# ESP32-S31 register map
Vendor: ESPRESSIF SYSTEMS (SHANGHAI) CO., LTD.; Series: ESP32 S-Series; File version: 1
CPU: RV32IMAFC r0p0, little endian, no MPU, FPU, 0 interrupt priority bits
Address unit: 32 bits
Registers are 32-bit, read-write, reset 0x0 unless marked. A register's access mark holds for its fields unless they carry their own. Offsets are from the block's base; [hi:lo] are bit positions; {n}, {i} and the like mark numbered series.

## SOC_ETM (part 4 of 4) — Event Task Matrix
Base 0x20393000
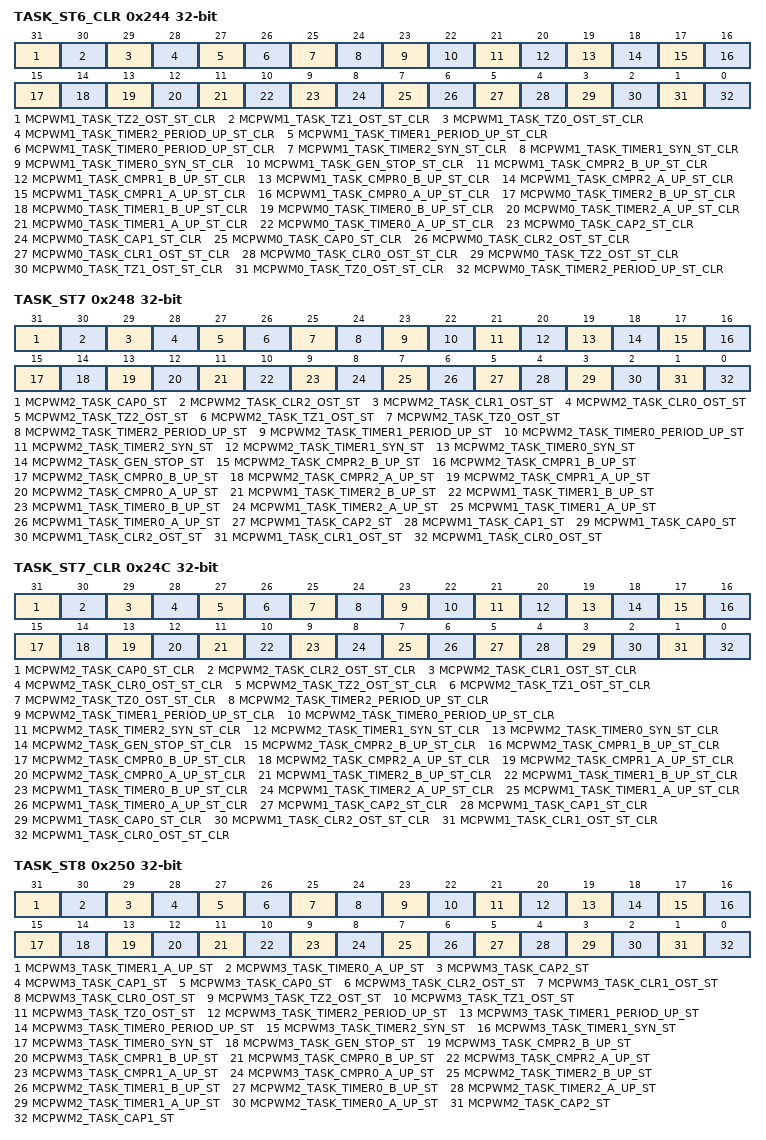
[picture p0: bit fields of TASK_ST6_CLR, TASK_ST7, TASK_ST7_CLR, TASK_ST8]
0x244 TASK_ST6_CLR wo — Tasks trigger status clear register
  [31] MCPWM1_TASK_TZ2_OST_ST_CLR — Configures whether or not to clear MCPWM1_task_tz2_ost trigger status.\\0: Invalid, No effect\\1: Clear
  [30] MCPWM1_TASK_TZ1_OST_ST_CLR — Configures whether or not to clear MCPWM1_task_tz1_ost trigger status.\\0: Invalid, No effect\\1: Clear
  [29] MCPWM1_TASK_TZ0_OST_ST_CLR — Configures whether or not to clear MCPWM1_task_tz0_ost trigger status.\\0: Invalid, No effect\\1: Clear
  [28] MCPWM1_TASK_TIMER2_PERIOD_UP_ST_CLR — Configures whether or not to clear MCPWM1_task_timer2_period_up trigger status.\\0: Invalid, No effect\\1: Clear
  [27] MCPWM1_TASK_TIMER1_PERIOD_UP_ST_CLR — Configures whether or not to clear MCPWM1_task_timer1_period_up trigger status.\\0: Invalid, No effect\\1: Clear
  [26] MCPWM1_TASK_TIMER0_PERIOD_UP_ST_CLR — Configures whether or not to clear MCPWM1_task_timer0_period_up trigger status.\\0: Invalid, No effect\\1: Clear
  [25] MCPWM1_TASK_TIMER2_SYN_ST_CLR — Configures whether or not to clear MCPWM1_task_timer2_syn trigger status.\\0: Invalid, No effect\\1: Clear
  [24] MCPWM1_TASK_TIMER1_SYN_ST_CLR — Configures whether or not to clear MCPWM1_task_timer1_syn trigger status.\\0: Invalid, No effect\\1: Clear
  [23] MCPWM1_TASK_TIMER0_SYN_ST_CLR — Configures whether or not to clear MCPWM1_task_timer0_syn trigger status.\\0: Invalid, No effect\\1: Clear
  [22] MCPWM1_TASK_GEN_STOP_ST_CLR — Configures whether or not to clear MCPWM1_task_gen_stop trigger status.\\0: Invalid, No effect\\1: Clear
  [21] MCPWM1_TASK_CMPR2_B_UP_ST_CLR — Configures whether or not to clear MCPWM1_task_cmpr2_b_up trigger status.\\0: Invalid, No effect\\1: Clear
  [20] MCPWM1_TASK_CMPR1_B_UP_ST_CLR — Configures whether or not to clear MCPWM1_task_cmpr1_b_up trigger status.\\0: Invalid, No effect\\1: Clear
  [19] MCPWM1_TASK_CMPR0_B_UP_ST_CLR — Configures whether or not to clear MCPWM1_task_cmpr0_b_up trigger status.\\0: Invalid, No effect\\1: Clear
  [18] MCPWM1_TASK_CMPR2_A_UP_ST_CLR — Configures whether or not to clear MCPWM1_task_cmpr2_a_up trigger status.\\0: Invalid, No effect\\1: Clear
  [17] MCPWM1_TASK_CMPR1_A_UP_ST_CLR — Configures whether or not to clear MCPWM1_task_cmpr1_a_up trigger status.\\0: Invalid, No effect\\1: Clear
  [16] MCPWM1_TASK_CMPR0_A_UP_ST_CLR — Configures whether or not to clear MCPWM1_task_cmpr0_a_up trigger status.\\0: Invalid, No effect\\1: Clear
  [15] MCPWM0_TASK_TIMER2_B_UP_ST_CLR — Configures whether or not to clear MCPWM0_task_timer2_b_up trigger status.\\0: Invalid, No effect\\1: Clear
  [14] MCPWM0_TASK_TIMER1_B_UP_ST_CLR — Configures whether or not to clear MCPWM0_task_timer1_b_up trigger status.\\0: Invalid, No effect\\1: Clear
  [13] MCPWM0_TASK_TIMER0_B_UP_ST_CLR — Configures whether or not to clear MCPWM0_task_timer0_b_up trigger status.\\0: Invalid, No effect\\1: Clear
  [12] MCPWM0_TASK_TIMER2_A_UP_ST_CLR — Configures whether or not to clear MCPWM0_task_timer2_a_up trigger status.\\0: Invalid, No effect\\1: Clear
  [11] MCPWM0_TASK_TIMER1_A_UP_ST_CLR — Configures whether or not to clear MCPWM0_task_timer1_a_up trigger status.\\0: Invalid, No effect\\1: Clear
  [10] MCPWM0_TASK_TIMER0_A_UP_ST_CLR — Configures whether or not to clear MCPWM0_task_timer0_a_up trigger status.\\0: Invalid, No effect\\1: Clear
  [9] MCPWM0_TASK_CAP2_ST_CLR — Configures whether or not to clear MCPWM0_task_cap2 trigger status.\\0: Invalid, No effect\\1: Clear
  [8] MCPWM0_TASK_CAP1_ST_CLR — Configures whether or not to clear MCPWM0_task_cap1 trigger status.\\0: Invalid, No effect\\1: Clear
  [7] MCPWM0_TASK_CAP0_ST_CLR — Configures whether or not to clear MCPWM0_task_cap0 trigger status.\\0: Invalid, No effect\\1: Clear
  [6] MCPWM0_TASK_CLR2_OST_ST_CLR — Configures whether or not to clear MCPWM0_task_clr2_ost trigger status.\\0: Invalid, No effect\\1: Clear
  [5] MCPWM0_TASK_CLR1_OST_ST_CLR — Configures whether or not to clear MCPWM0_task_clr1_ost trigger status.\\0: Invalid, No effect\\1: Clear
  [4] MCPWM0_TASK_CLR0_OST_ST_CLR — Configures whether or not to clear MCPWM0_task_clr0_ost trigger status.\\0: Invalid, No effect\\1: Clear
  [3] MCPWM0_TASK_TZ2_OST_ST_CLR — Configures whether or not to clear MCPWM0_task_tz2_ost trigger status.\\0: Invalid, No effect\\1: Clear
  [2] MCPWM0_TASK_TZ1_OST_ST_CLR — Configures whether or not to clear MCPWM0_task_tz1_ost trigger status.\\0: Invalid, No effect\\1: Clear
  [1] MCPWM0_TASK_TZ0_OST_ST_CLR — Configures whether or not to clear MCPWM0_task_tz0_ost trigger status.\\0: Invalid, No effect\\1: Clear
  [0] MCPWM0_TASK_TIMER2_PERIOD_UP_ST_CLR — Configures whether or not to clear MCPWM0_task_timer2_period_up trigger status.\\0: Invalid, No effect\\1: Clear
0x248 TASK_ST7 — Tasks trigger status register
  [31] MCPWM2_TASK_CAP0_ST — Represents MCPWM2_task_cap0 trigger status.\\0: Not triggered\\1: Triggered
  [30] MCPWM2_TASK_CLR2_OST_ST — Represents MCPWM2_task_clr2_ost trigger status.\\0: Not triggered\\1: Triggered
  [29] MCPWM2_TASK_CLR1_OST_ST — Represents MCPWM2_task_clr1_ost trigger status.\\0: Not triggered\\1: Triggered
  [28] MCPWM2_TASK_CLR0_OST_ST — Represents MCPWM2_task_clr0_ost trigger status.\\0: Not triggered\\1: Triggered
  [27] MCPWM2_TASK_TZ2_OST_ST — Represents MCPWM2_task_tz2_ost trigger status.\\0: Not triggered\\1: Triggered
  [26] MCPWM2_TASK_TZ1_OST_ST — Represents MCPWM2_task_tz1_ost trigger status.\\0: Not triggered\\1: Triggered
  [25] MCPWM2_TASK_TZ0_OST_ST — Represents MCPWM2_task_tz0_ost trigger status.\\0: Not triggered\\1: Triggered
  [24] MCPWM2_TASK_TIMER2_PERIOD_UP_ST — Represents MCPWM2_task_timer2_period_up trigger status.\\0: Not triggered\\1: Triggered
  [23] MCPWM2_TASK_TIMER1_PERIOD_UP_ST — Represents MCPWM2_task_timer1_period_up trigger status.\\0: Not triggered\\1: Triggered
  [22] MCPWM2_TASK_TIMER0_PERIOD_UP_ST — Represents MCPWM2_task_timer0_period_up trigger status.\\0: Not triggered\\1: Triggered
  [21] MCPWM2_TASK_TIMER2_SYN_ST — Represents MCPWM2_task_timer2_syn trigger status.\\0: Not triggered\\1: Triggered
  [20] MCPWM2_TASK_TIMER1_SYN_ST — Represents MCPWM2_task_timer1_syn trigger status.\\0: Not triggered\\1: Triggered
  [19] MCPWM2_TASK_TIMER0_SYN_ST — Represents MCPWM2_task_timer0_syn trigger status.\\0: Not triggered\\1: Triggered
  [18] MCPWM2_TASK_GEN_STOP_ST — Represents MCPWM2_task_gen_stop trigger status.\\0: Not triggered\\1: Triggered
  [17] MCPWM2_TASK_CMPR2_B_UP_ST — Represents MCPWM2_task_cmpr2_b_up trigger status.\\0: Not triggered\\1: Triggered
  [16] MCPWM2_TASK_CMPR1_B_UP_ST — Represents MCPWM2_task_cmpr1_b_up trigger status.\\0: Not triggered\\1: Triggered
  [15] MCPWM2_TASK_CMPR0_B_UP_ST — Represents MCPWM2_task_cmpr0_b_up trigger status.\\0: Not triggered\\1: Triggered
  [14] MCPWM2_TASK_CMPR2_A_UP_ST — Represents MCPWM2_task_cmpr2_a_up trigger status.\\0: Not triggered\\1: Triggered
  [13] MCPWM2_TASK_CMPR1_A_UP_ST — Represents MCPWM2_task_cmpr1_a_up trigger status.\\0: Not triggered\\1: Triggered
  [12] MCPWM2_TASK_CMPR0_A_UP_ST — Represents MCPWM2_task_cmpr0_a_up trigger status.\\0: Not triggered\\1: Triggered
  [11] MCPWM1_TASK_TIMER2_B_UP_ST — Represents MCPWM1_task_timer2_b_up trigger status.\\0: Not triggered\\1: Triggered
  [10] MCPWM1_TASK_TIMER1_B_UP_ST — Represents MCPWM1_task_timer1_b_up trigger status.\\0: Not triggered\\1: Triggered
  [9] MCPWM1_TASK_TIMER0_B_UP_ST — Represents MCPWM1_task_timer0_b_up trigger status.\\0: Not triggered\\1: Triggered
  [8] MCPWM1_TASK_TIMER2_A_UP_ST — Represents MCPWM1_task_timer2_a_up trigger status.\\0: Not triggered\\1: Triggered
  [7] MCPWM1_TASK_TIMER1_A_UP_ST — Represents MCPWM1_task_timer1_a_up trigger status.\\0: Not triggered\\1: Triggered
  [6] MCPWM1_TASK_TIMER0_A_UP_ST — Represents MCPWM1_task_timer0_a_up trigger status.\\0: Not triggered\\1: Triggered
  [5] MCPWM1_TASK_CAP2_ST — Represents MCPWM1_task_cap2 trigger status.\\0: Not triggered\\1: Triggered
  [4] MCPWM1_TASK_CAP1_ST — Represents MCPWM1_task_cap1 trigger status.\\0: Not triggered\\1: Triggered
  [3] MCPWM1_TASK_CAP0_ST — Represents MCPWM1_task_cap0 trigger status.\\0: Not triggered\\1: Triggered
  [2] MCPWM1_TASK_CLR2_OST_ST — Represents MCPWM1_task_clr2_ost trigger status.\\0: Not triggered\\1: Triggered
  [1] MCPWM1_TASK_CLR1_OST_ST — Represents MCPWM1_task_clr1_ost trigger status.\\0: Not triggered\\1: Triggered
  [0] MCPWM1_TASK_CLR0_OST_ST — Represents MCPWM1_task_clr0_ost trigger status.\\0: Not triggered\\1: Triggered
0x24C TASK_ST7_CLR wo — Tasks trigger status clear register
  [31] MCPWM2_TASK_CAP0_ST_CLR — Configures whether or not to clear MCPWM2_task_cap0 trigger status.\\0: Invalid, No effect\\1: Clear
  [30] MCPWM2_TASK_CLR2_OST_ST_CLR — Configures whether or not to clear MCPWM2_task_clr2_ost trigger status.\\0: Invalid, No effect\\1: Clear
  [29] MCPWM2_TASK_CLR1_OST_ST_CLR — Configures whether or not to clear MCPWM2_task_clr1_ost trigger status.\\0: Invalid, No effect\\1: Clear
  [28] MCPWM2_TASK_CLR0_OST_ST_CLR — Configures whether or not to clear MCPWM2_task_clr0_ost trigger status.\\0: Invalid, No effect\\1: Clear
  [27] MCPWM2_TASK_TZ2_OST_ST_CLR — Configures whether or not to clear MCPWM2_task_tz2_ost trigger status.\\0: Invalid, No effect\\1: Clear
  [26] MCPWM2_TASK_TZ1_OST_ST_CLR — Configures whether or not to clear MCPWM2_task_tz1_ost trigger status.\\0: Invalid, No effect\\1: Clear
  [25] MCPWM2_TASK_TZ0_OST_ST_CLR — Configures whether or not to clear MCPWM2_task_tz0_ost trigger status.\\0: Invalid, No effect\\1: Clear
  [24] MCPWM2_TASK_TIMER2_PERIOD_UP_ST_CLR — Configures whether or not to clear MCPWM2_task_timer2_period_up trigger status.\\0: Invalid, No effect\\1: Clear
  [23] MCPWM2_TASK_TIMER1_PERIOD_UP_ST_CLR — Configures whether or not to clear MCPWM2_task_timer1_period_up trigger status.\\0: Invalid, No effect\\1: Clear
  [22] MCPWM2_TASK_TIMER0_PERIOD_UP_ST_CLR — Configures whether or not to clear MCPWM2_task_timer0_period_up trigger status.\\0: Invalid, No effect\\1: Clear
  [21] MCPWM2_TASK_TIMER2_SYN_ST_CLR — Configures whether or not to clear MCPWM2_task_timer2_syn trigger status.\\0: Invalid, No effect\\1: Clear
  [20] MCPWM2_TASK_TIMER1_SYN_ST_CLR — Configures whether or not to clear MCPWM2_task_timer1_syn trigger status.\\0: Invalid, No effect\\1: Clear
  [19] MCPWM2_TASK_TIMER0_SYN_ST_CLR — Configures whether or not to clear MCPWM2_task_timer0_syn trigger status.\\0: Invalid, No effect\\1: Clear
  [18] MCPWM2_TASK_GEN_STOP_ST_CLR — Configures whether or not to clear MCPWM2_task_gen_stop trigger status.\\0: Invalid, No effect\\1: Clear
  [17] MCPWM2_TASK_CMPR2_B_UP_ST_CLR — Configures whether or not to clear MCPWM2_task_cmpr2_b_up trigger status.\\0: Invalid, No effect\\1: Clear
  [16] MCPWM2_TASK_CMPR1_B_UP_ST_CLR — Configures whether or not to clear MCPWM2_task_cmpr1_b_up trigger status.\\0: Invalid, No effect\\1: Clear
  [15] MCPWM2_TASK_CMPR0_B_UP_ST_CLR — Configures whether or not to clear MCPWM2_task_cmpr0_b_up trigger status.\\0: Invalid, No effect\\1: Clear
  [14] MCPWM2_TASK_CMPR2_A_UP_ST_CLR — Configures whether or not to clear MCPWM2_task_cmpr2_a_up trigger status.\\0: Invalid, No effect\\1: Clear
  [13] MCPWM2_TASK_CMPR1_A_UP_ST_CLR — Configures whether or not to clear MCPWM2_task_cmpr1_a_up trigger status.\\0: Invalid, No effect\\1: Clear
  [12] MCPWM2_TASK_CMPR0_A_UP_ST_CLR — Configures whether or not to clear MCPWM2_task_cmpr0_a_up trigger status.\\0: Invalid, No effect\\1: Clear
  [11] MCPWM1_TASK_TIMER2_B_UP_ST_CLR — Configures whether or not to clear MCPWM1_task_timer2_b_up trigger status.\\0: Invalid, No effect\\1: Clear
  [10] MCPWM1_TASK_TIMER1_B_UP_ST_CLR — Configures whether or not to clear MCPWM1_task_timer1_b_up trigger status.\\0: Invalid, No effect\\1: Clear
  [9] MCPWM1_TASK_TIMER0_B_UP_ST_CLR — Configures whether or not to clear MCPWM1_task_timer0_b_up trigger status.\\0: Invalid, No effect\\1: Clear
  [8] MCPWM1_TASK_TIMER2_A_UP_ST_CLR — Configures whether or not to clear MCPWM1_task_timer2_a_up trigger status.\\0: Invalid, No effect\\1: Clear
  [7] MCPWM1_TASK_TIMER1_A_UP_ST_CLR — Configures whether or not to clear MCPWM1_task_timer1_a_up trigger status.\\0: Invalid, No effect\\1: Clear
  [6] MCPWM1_TASK_TIMER0_A_UP_ST_CLR — Configures whether or not to clear MCPWM1_task_timer0_a_up trigger status.\\0: Invalid, No effect\\1: Clear
  [5] MCPWM1_TASK_CAP2_ST_CLR — Configures whether or not to clear MCPWM1_task_cap2 trigger status.\\0: Invalid, No effect\\1: Clear
  [4] MCPWM1_TASK_CAP1_ST_CLR — Configures whether or not to clear MCPWM1_task_cap1 trigger status.\\0: Invalid, No effect\\1: Clear
  [3] MCPWM1_TASK_CAP0_ST_CLR — Configures whether or not to clear MCPWM1_task_cap0 trigger status.\\0: Invalid, No effect\\1: Clear
  [2] MCPWM1_TASK_CLR2_OST_ST_CLR — Configures whether or not to clear MCPWM1_task_clr2_ost trigger status.\\0: Invalid, No effect\\1: Clear
  [1] MCPWM1_TASK_CLR1_OST_ST_CLR — Configures whether or not to clear MCPWM1_task_clr1_ost trigger status.\\0: Invalid, No effect\\1: Clear
  [0] MCPWM1_TASK_CLR0_OST_ST_CLR — Configures whether or not to clear MCPWM1_task_clr0_ost trigger status.\\0: Invalid, No effect\\1: Clear
0x250 TASK_ST8 — Tasks trigger status register
  [31] MCPWM3_TASK_TIMER1_A_UP_ST — Represents MCPWM3_task_timer1_a_up trigger status.\\0: Not triggered\\1: Triggered
  [30] MCPWM3_TASK_TIMER0_A_UP_ST — Represents MCPWM3_task_timer0_a_up trigger status.\\0: Not triggered\\1: Triggered
  [29] MCPWM3_TASK_CAP2_ST — Represents MCPWM3_task_cap2 trigger status.\\0: Not triggered\\1: Triggered
  [28] MCPWM3_TASK_CAP1_ST — Represents MCPWM3_task_cap1 trigger status.\\0: Not triggered\\1: Triggered
  [27] MCPWM3_TASK_CAP0_ST — Represents MCPWM3_task_cap0 trigger status.\\0: Not triggered\\1: Triggered
  [26] MCPWM3_TASK_CLR2_OST_ST — Represents MCPWM3_task_clr2_ost trigger status.\\0: Not triggered\\1: Triggered
  [25] MCPWM3_TASK_CLR1_OST_ST — Represents MCPWM3_task_clr1_ost trigger status.\\0: Not triggered\\1: Triggered
  [24] MCPWM3_TASK_CLR0_OST_ST — Represents MCPWM3_task_clr0_ost trigger status.\\0: Not triggered\\1: Triggered
  [23] MCPWM3_TASK_TZ2_OST_ST — Represents MCPWM3_task_tz2_ost trigger status.\\0: Not triggered\\1: Triggered
  [22] MCPWM3_TASK_TZ1_OST_ST — Represents MCPWM3_task_tz1_ost trigger status.\\0: Not triggered\\1: Triggered
  [21] MCPWM3_TASK_TZ0_OST_ST — Represents MCPWM3_task_tz0_ost trigger status.\\0: Not triggered\\1: Triggered
  [20] MCPWM3_TASK_TIMER2_PERIOD_UP_ST — Represents MCPWM3_task_timer2_period_up trigger status.\\0: Not triggered\\1: Triggered
  [19] MCPWM3_TASK_TIMER1_PERIOD_UP_ST — Represents MCPWM3_task_timer1_period_up trigger status.\\0: Not triggered\\1: Triggered
  [18] MCPWM3_TASK_TIMER0_PERIOD_UP_ST — Represents MCPWM3_task_timer0_period_up trigger status.\\0: Not triggered\\1: Triggered
  [17] MCPWM3_TASK_TIMER2_SYN_ST — Represents MCPWM3_task_timer2_syn trigger status.\\0: Not triggered\\1: Triggered
  [16] MCPWM3_TASK_TIMER1_SYN_ST — Represents MCPWM3_task_timer1_syn trigger status.\\0: Not triggered\\1: Triggered
  [15] MCPWM3_TASK_TIMER0_SYN_ST — Represents MCPWM3_task_timer0_syn trigger status.\\0: Not triggered\\1: Triggered
  [14] MCPWM3_TASK_GEN_STOP_ST — Represents MCPWM3_task_gen_stop trigger status.\\0: Not triggered\\1: Triggered
  [13] MCPWM3_TASK_CMPR2_B_UP_ST — Represents MCPWM3_task_cmpr2_b_up trigger status.\\0: Not triggered\\1: Triggered
  [12] MCPWM3_TASK_CMPR1_B_UP_ST — Represents MCPWM3_task_cmpr1_b_up trigger status.\\0: Not triggered\\1: Triggered
  [11] MCPWM3_TASK_CMPR0_B_UP_ST — Represents MCPWM3_task_cmpr0_b_up trigger status.\\0: Not triggered\\1: Triggered
  [10] MCPWM3_TASK_CMPR2_A_UP_ST — Represents MCPWM3_task_cmpr2_a_up trigger status.\\0: Not triggered\\1: Triggered
  [9] MCPWM3_TASK_CMPR1_A_UP_ST — Represents MCPWM3_task_cmpr1_a_up trigger status.\\0: Not triggered\\1: Triggered
  [8] MCPWM3_TASK_CMPR0_A_UP_ST — Represents MCPWM3_task_cmpr0_a_up trigger status.\\0: Not triggered\\1: Triggered
  [7] MCPWM2_TASK_TIMER2_B_UP_ST — Represents MCPWM2_task_timer2_b_up trigger status.\\0: Not triggered\\1: Triggered
  [6] MCPWM2_TASK_TIMER1_B_UP_ST — Represents MCPWM2_task_timer1_b_up trigger status.\\0: Not triggered\\1: Triggered
  [5] MCPWM2_TASK_TIMER0_B_UP_ST — Represents MCPWM2_task_timer0_b_up trigger status.\\0: Not triggered\\1: Triggered
  [4] MCPWM2_TASK_TIMER2_A_UP_ST — Represents MCPWM2_task_timer2_a_up trigger status.\\0: Not triggered\\1: Triggered
  [3] MCPWM2_TASK_TIMER1_A_UP_ST — Represents MCPWM2_task_timer1_a_up trigger status.\\0: Not triggered\\1: Triggered
  [2] MCPWM2_TASK_TIMER0_A_UP_ST — Represents MCPWM2_task_timer0_a_up trigger status.\\0: Not triggered\\1: Triggered
  [1] MCPWM2_TASK_CAP2_ST — Represents MCPWM2_task_cap2 trigger status.\\0: Not triggered\\1: Triggered
  [0] MCPWM2_TASK_CAP1_ST — Represents MCPWM2_task_cap1 trigger status.\\0: Not triggered\\1: Triggered
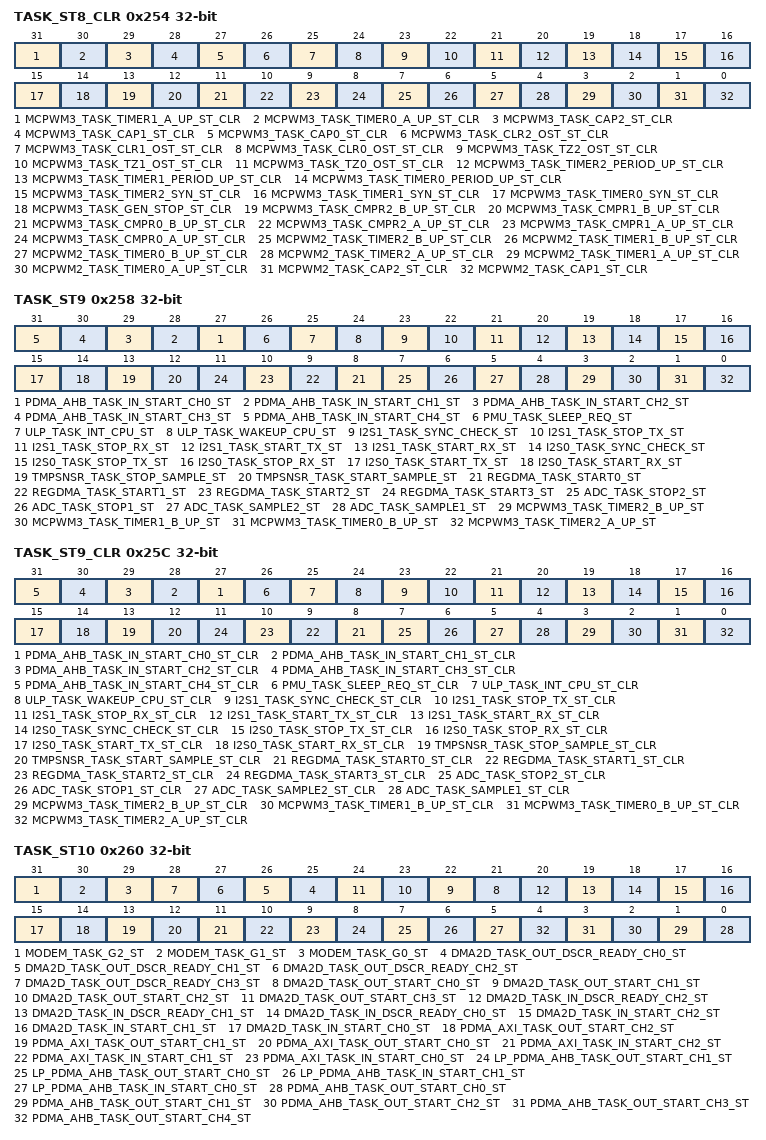
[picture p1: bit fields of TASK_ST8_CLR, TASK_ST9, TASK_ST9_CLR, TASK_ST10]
0x254 TASK_ST8_CLR wo — Tasks trigger status clear register
  [31] MCPWM3_TASK_TIMER1_A_UP_ST_CLR — Configures whether or not to clear MCPWM3_task_timer1_a_up trigger status.\\0: Invalid, No effect\\1: Clear
  [30] MCPWM3_TASK_TIMER0_A_UP_ST_CLR — Configures whether or not to clear MCPWM3_task_timer0_a_up trigger status.\\0: Invalid, No effect\\1: Clear
  [29] MCPWM3_TASK_CAP2_ST_CLR — Configures whether or not to clear MCPWM3_task_cap2 trigger status.\\0: Invalid, No effect\\1: Clear
  [28] MCPWM3_TASK_CAP1_ST_CLR — Configures whether or not to clear MCPWM3_task_cap1 trigger status.\\0: Invalid, No effect\\1: Clear
  [27] MCPWM3_TASK_CAP0_ST_CLR — Configures whether or not to clear MCPWM3_task_cap0 trigger status.\\0: Invalid, No effect\\1: Clear
  [26] MCPWM3_TASK_CLR2_OST_ST_CLR — Configures whether or not to clear MCPWM3_task_clr2_ost trigger status.\\0: Invalid, No effect\\1: Clear
  [25] MCPWM3_TASK_CLR1_OST_ST_CLR — Configures whether or not to clear MCPWM3_task_clr1_ost trigger status.\\0: Invalid, No effect\\1: Clear
  [24] MCPWM3_TASK_CLR0_OST_ST_CLR — Configures whether or not to clear MCPWM3_task_clr0_ost trigger status.\\0: Invalid, No effect\\1: Clear
  [23] MCPWM3_TASK_TZ2_OST_ST_CLR — Configures whether or not to clear MCPWM3_task_tz2_ost trigger status.\\0: Invalid, No effect\\1: Clear
  [22] MCPWM3_TASK_TZ1_OST_ST_CLR — Configures whether or not to clear MCPWM3_task_tz1_ost trigger status.\\0: Invalid, No effect\\1: Clear
  [21] MCPWM3_TASK_TZ0_OST_ST_CLR — Configures whether or not to clear MCPWM3_task_tz0_ost trigger status.\\0: Invalid, No effect\\1: Clear
  [20] MCPWM3_TASK_TIMER2_PERIOD_UP_ST_CLR — Configures whether or not to clear MCPWM3_task_timer2_period_up trigger status.\\0: Invalid, No effect\\1: Clear
  [19] MCPWM3_TASK_TIMER1_PERIOD_UP_ST_CLR — Configures whether or not to clear MCPWM3_task_timer1_period_up trigger status.\\0: Invalid, No effect\\1: Clear
  [18] MCPWM3_TASK_TIMER0_PERIOD_UP_ST_CLR — Configures whether or not to clear MCPWM3_task_timer0_period_up trigger status.\\0: Invalid, No effect\\1: Clear
  [17] MCPWM3_TASK_TIMER2_SYN_ST_CLR — Configures whether or not to clear MCPWM3_task_timer2_syn trigger status.\\0: Invalid, No effect\\1: Clear
  [16] MCPWM3_TASK_TIMER1_SYN_ST_CLR — Configures whether or not to clear MCPWM3_task_timer1_syn trigger status.\\0: Invalid, No effect\\1: Clear
  [15] MCPWM3_TASK_TIMER0_SYN_ST_CLR — Configures whether or not to clear MCPWM3_task_timer0_syn trigger status.\\0: Invalid, No effect\\1: Clear
  [14] MCPWM3_TASK_GEN_STOP_ST_CLR — Configures whether or not to clear MCPWM3_task_gen_stop trigger status.\\0: Invalid, No effect\\1: Clear
  [13] MCPWM3_TASK_CMPR2_B_UP_ST_CLR — Configures whether or not to clear MCPWM3_task_cmpr2_b_up trigger status.\\0: Invalid, No effect\\1: Clear
  [12] MCPWM3_TASK_CMPR1_B_UP_ST_CLR — Configures whether or not to clear MCPWM3_task_cmpr1_b_up trigger status.\\0: Invalid, No effect\\1: Clear
  [11] MCPWM3_TASK_CMPR0_B_UP_ST_CLR — Configures whether or not to clear MCPWM3_task_cmpr0_b_up trigger status.\\0: Invalid, No effect\\1: Clear
  [10] MCPWM3_TASK_CMPR2_A_UP_ST_CLR — Configures whether or not to clear MCPWM3_task_cmpr2_a_up trigger status.\\0: Invalid, No effect\\1: Clear
  [9] MCPWM3_TASK_CMPR1_A_UP_ST_CLR — Configures whether or not to clear MCPWM3_task_cmpr1_a_up trigger status.\\0: Invalid, No effect\\1: Clear
  [8] MCPWM3_TASK_CMPR0_A_UP_ST_CLR — Configures whether or not to clear MCPWM3_task_cmpr0_a_up trigger status.\\0: Invalid, No effect\\1: Clear
  [7] MCPWM2_TASK_TIMER2_B_UP_ST_CLR — Configures whether or not to clear MCPWM2_task_timer2_b_up trigger status.\\0: Invalid, No effect\\1: Clear
  [6] MCPWM2_TASK_TIMER1_B_UP_ST_CLR — Configures whether or not to clear MCPWM2_task_timer1_b_up trigger status.\\0: Invalid, No effect\\1: Clear
  [5] MCPWM2_TASK_TIMER0_B_UP_ST_CLR — Configures whether or not to clear MCPWM2_task_timer0_b_up trigger status.\\0: Invalid, No effect\\1: Clear
  [4] MCPWM2_TASK_TIMER2_A_UP_ST_CLR — Configures whether or not to clear MCPWM2_task_timer2_a_up trigger status.\\0: Invalid, No effect\\1: Clear
  [3] MCPWM2_TASK_TIMER1_A_UP_ST_CLR — Configures whether or not to clear MCPWM2_task_timer1_a_up trigger status.\\0: Invalid, No effect\\1: Clear
  [2] MCPWM2_TASK_TIMER0_A_UP_ST_CLR — Configures whether or not to clear MCPWM2_task_timer0_a_up trigger status.\\0: Invalid, No effect\\1: Clear
  [1] MCPWM2_TASK_CAP2_ST_CLR — Configures whether or not to clear MCPWM2_task_cap2 trigger status.\\0: Invalid, No effect\\1: Clear
  [0] MCPWM2_TASK_CAP1_ST_CLR — Configures whether or not to clear MCPWM2_task_cap1 trigger status.\\0: Invalid, No effect\\1: Clear
0x258 TASK_ST9 — Tasks trigger status register
  [n+27] PDMA_AHB_TASK_IN_START_CH{n}_ST (n=0..4) — Represents PDMA_AHB_task_in_start_ch{n} trigger status.\\0: Not triggered\\1: Triggered
  [26] PMU_TASK_SLEEP_REQ_ST — Represents PMU_task_sleep_req trigger status.\\0: Not triggered\\1: Triggered
  [25] ULP_TASK_INT_CPU_ST — Represents ULP_task_int_cpu trigger status.\\0: Not triggered\\1: Triggered
  [24] ULP_TASK_WAKEUP_CPU_ST — Represents ULP_task_wakeup_cpu trigger status.\\0: Not triggered\\1: Triggered
  [23] I2S1_TASK_SYNC_CHECK_ST — Represents I2S1_task_sync_check trigger status.\\0: Not triggered\\1: Triggered
  [22] I2S1_TASK_STOP_TX_ST — Represents I2S1_task_stop_tx trigger status.\\0: Not triggered\\1: Triggered
  [21] I2S1_TASK_STOP_RX_ST — Represents I2S1_task_stop_rx trigger status.\\0: Not triggered\\1: Triggered
  [20] I2S1_TASK_START_TX_ST — Represents I2S1_task_start_tx trigger status.\\0: Not triggered\\1: Triggered
  [19] I2S1_TASK_START_RX_ST — Represents I2S1_task_start_rx trigger status.\\0: Not triggered\\1: Triggered
  [18] I2S0_TASK_SYNC_CHECK_ST — Represents I2S0_task_sync_check trigger status.\\0: Not triggered\\1: Triggered
  [17] I2S0_TASK_STOP_TX_ST — Represents I2S0_task_stop_tx trigger status.\\0: Not triggered\\1: Triggered
  [16] I2S0_TASK_STOP_RX_ST — Represents I2S0_task_stop_rx trigger status.\\0: Not triggered\\1: Triggered
  [15] I2S0_TASK_START_TX_ST — Represents I2S0_task_start_tx trigger status.\\0: Not triggered\\1: Triggered
  [14] I2S0_TASK_START_RX_ST — Represents I2S0_task_start_rx trigger status.\\0: Not triggered\\1: Triggered
  [13] TMPSNSR_TASK_STOP_SAMPLE_ST — Represents TMPSNSR_task_stop_sample trigger status.\\0: Not triggered\\1: Triggered
  [12] TMPSNSR_TASK_START_SAMPLE_ST — Represents TMPSNSR_task_start_sample trigger status.\\0: Not triggered\\1: Triggered
  [n+8] REGDMA_TASK_START{n}_ST (n=0..3) — Represents REGDMA_task_start{n} trigger status.\\0: Not triggered\\1: Triggered
  [7] ADC_TASK_STOP2_ST — Represents ADC_task_stop2 trigger status.\\0: Not triggered\\1: Triggered
  [6] ADC_TASK_STOP1_ST — Represents ADC_task_stop1 trigger status.\\0: Not triggered\\1: Triggered
  [5] ADC_TASK_SAMPLE2_ST — Represents ADC_task_sample2 trigger status.\\0: Not triggered\\1: Triggered
  [4] ADC_TASK_SAMPLE1_ST — Represents ADC_task_sample1 trigger status.\\0: Not triggered\\1: Triggered
  [3] MCPWM3_TASK_TIMER2_B_UP_ST — Represents MCPWM3_task_timer2_b_up trigger status.\\0: Not triggered\\1: Triggered
  [2] MCPWM3_TASK_TIMER1_B_UP_ST — Represents MCPWM3_task_timer1_b_up trigger status.\\0: Not triggered\\1: Triggered
  [1] MCPWM3_TASK_TIMER0_B_UP_ST — Represents MCPWM3_task_timer0_b_up trigger status.\\0: Not triggered\\1: Triggered
  [0] MCPWM3_TASK_TIMER2_A_UP_ST — Represents MCPWM3_task_timer2_a_up trigger status.\\0: Not triggered\\1: Triggered
0x25C TASK_ST9_CLR wo — Tasks trigger status clear register
  [n+27] PDMA_AHB_TASK_IN_START_CH{n}_ST_CLR (n=0..4) — Configures whether or not to clear PDMA_AHB_task_in_start_ch{n} trigger status.\\0: Invalid, No effect\\1: Clear
  [26] PMU_TASK_SLEEP_REQ_ST_CLR — Configures whether or not to clear PMU_task_sleep_req trigger status.\\0: Invalid, No effect\\1: Clear
  [25] ULP_TASK_INT_CPU_ST_CLR — Configures whether or not to clear ULP_task_int_cpu trigger status.\\0: Invalid, No effect\\1: Clear
  [24] ULP_TASK_WAKEUP_CPU_ST_CLR — Configures whether or not to clear ULP_task_wakeup_cpu trigger status.\\0: Invalid, No effect\\1: Clear
  [23] I2S1_TASK_SYNC_CHECK_ST_CLR — Configures whether or not to clear I2S1_task_sync_check trigger status.\\0: Invalid, No effect\\1: Clear
  [22] I2S1_TASK_STOP_TX_ST_CLR — Configures whether or not to clear I2S1_task_stop_tx trigger status.\\0: Invalid, No effect\\1: Clear
  [21] I2S1_TASK_STOP_RX_ST_CLR — Configures whether or not to clear I2S1_task_stop_rx trigger status.\\0: Invalid, No effect\\1: Clear
  [20] I2S1_TASK_START_TX_ST_CLR — Configures whether or not to clear I2S1_task_start_tx trigger status.\\0: Invalid, No effect\\1: Clear
  [19] I2S1_TASK_START_RX_ST_CLR — Configures whether or not to clear I2S1_task_start_rx trigger status.\\0: Invalid, No effect\\1: Clear
  [18] I2S0_TASK_SYNC_CHECK_ST_CLR — Configures whether or not to clear I2S0_task_sync_check trigger status.\\0: Invalid, No effect\\1: Clear
  [17] I2S0_TASK_STOP_TX_ST_CLR — Configures whether or not to clear I2S0_task_stop_tx trigger status.\\0: Invalid, No effect\\1: Clear
  [16] I2S0_TASK_STOP_RX_ST_CLR — Configures whether or not to clear I2S0_task_stop_rx trigger status.\\0: Invalid, No effect\\1: Clear
  [15] I2S0_TASK_START_TX_ST_CLR — Configures whether or not to clear I2S0_task_start_tx trigger status.\\0: Invalid, No effect\\1: Clear
  [14] I2S0_TASK_START_RX_ST_CLR — Configures whether or not to clear I2S0_task_start_rx trigger status.\\0: Invalid, No effect\\1: Clear
  [13] TMPSNSR_TASK_STOP_SAMPLE_ST_CLR — Configures whether or not to clear TMPSNSR_task_stop_sample trigger status.\\0: Invalid, No effect\\1: Clear
  [12] TMPSNSR_TASK_START_SAMPLE_ST_CLR — Configures whether or not to clear TMPSNSR_task_start_sample trigger status.\\0: Invalid, No effect\\1: Clear
  [n+8] REGDMA_TASK_START{n}_ST_CLR (n=0..3) — Configures whether or not to clear REGDMA_task_start{n} trigger status.\\0: Invalid, No effect\\1: Clear
  [7] ADC_TASK_STOP2_ST_CLR — Configures whether or not to clear ADC_task_stop2 trigger status.\\0: Invalid, No effect\\1: Clear
  [6] ADC_TASK_STOP1_ST_CLR — Configures whether or not to clear ADC_task_stop1 trigger status.\\0: Invalid, No effect\\1: Clear
  [5] ADC_TASK_SAMPLE2_ST_CLR — Configures whether or not to clear ADC_task_sample2 trigger status.\\0: Invalid, No effect\\1: Clear
  [4] ADC_TASK_SAMPLE1_ST_CLR — Configures whether or not to clear ADC_task_sample1 trigger status.\\0: Invalid, No effect\\1: Clear
  [3] MCPWM3_TASK_TIMER2_B_UP_ST_CLR — Configures whether or not to clear MCPWM3_task_timer2_b_up trigger status.\\0: Invalid, No effect\\1: Clear
  [2] MCPWM3_TASK_TIMER1_B_UP_ST_CLR — Configures whether or not to clear MCPWM3_task_timer1_b_up trigger status.\\0: Invalid, No effect\\1: Clear
  [1] MCPWM3_TASK_TIMER0_B_UP_ST_CLR — Configures whether or not to clear MCPWM3_task_timer0_b_up trigger status.\\0: Invalid, No effect\\1: Clear
  [0] MCPWM3_TASK_TIMER2_A_UP_ST_CLR — Configures whether or not to clear MCPWM3_task_timer2_a_up trigger status.\\0: Invalid, No effect\\1: Clear
0x260 TASK_ST10 — Tasks trigger status register
  [31] MODEM_TASK_G2_ST — Represents MODEM_task_g2 trigger status.\\0: Not triggered\\1: Triggered
  [30] MODEM_TASK_G1_ST — Represents MODEM_task_g1 trigger status.\\0: Not triggered\\1: Triggered
  [29] MODEM_TASK_G0_ST — Represents MODEM_task_g0 trigger status.\\0: Not triggered\\1: Triggered
  [n+25] DMA2D_TASK_OUT_DSCR_READY_CH{n}_ST (n=0..3) — Represents DMA2D_task_out_dscr_ready_ch{n} trigger status.\\0: Not triggered\\1: Triggered
  [n+21] DMA2D_TASK_OUT_START_CH{n}_ST (n=0..3) — Represents DMA2D_task_out_start_ch{n} trigger status.\\0: Not triggered\\1: Triggered
  [20] DMA2D_TASK_IN_DSCR_READY_CH2_ST — Represents DMA2D_task_in_dscr_ready_ch2 trigger status.\\0: Not triggered\\1: Triggered
  [19] DMA2D_TASK_IN_DSCR_READY_CH1_ST — Represents DMA2D_task_in_dscr_ready_ch1 trigger status.\\0: Not triggered\\1: Triggered
  [18] DMA2D_TASK_IN_DSCR_READY_CH0_ST — Represents DMA2D_task_in_dscr_ready_ch0 trigger status.\\0: Not triggered\\1: Triggered
  [17] DMA2D_TASK_IN_START_CH2_ST — Represents DMA2D_task_in_start_ch2 trigger status.\\0: Not triggered\\1: Triggered
  [16] DMA2D_TASK_IN_START_CH1_ST — Represents DMA2D_task_in_start_ch1 trigger status.\\0: Not triggered\\1: Triggered
  [15] DMA2D_TASK_IN_START_CH0_ST — Represents DMA2D_task_in_start_ch0 trigger status.\\0: Not triggered\\1: Triggered
  [14] PDMA_AXI_TASK_OUT_START_CH2_ST — Represents PDMA_AXI_task_out_start_ch2 trigger status.\\0: Not triggered\\1: Triggered
  [13] PDMA_AXI_TASK_OUT_START_CH1_ST — Represents PDMA_AXI_task_out_start_ch1 trigger status.\\0: Not triggered\\1: Triggered
  [12] PDMA_AXI_TASK_OUT_START_CH0_ST — Represents PDMA_AXI_task_out_start_ch0 trigger status.\\0: Not triggered\\1: Triggered
  [11] PDMA_AXI_TASK_IN_START_CH2_ST — Represents PDMA_AXI_task_in_start_ch2 trigger status.\\0: Not triggered\\1: Triggered
  [10] PDMA_AXI_TASK_IN_START_CH1_ST — Represents PDMA_AXI_task_in_start_ch1 trigger status.\\0: Not triggered\\1: Triggered
  [9] PDMA_AXI_TASK_IN_START_CH0_ST — Represents PDMA_AXI_task_in_start_ch0 trigger status.\\0: Not triggered\\1: Triggered
  [8] LP_PDMA_AHB_TASK_OUT_START_CH1_ST — Represents LP_PDMA_AHB_task_out_start_ch1 trigger status.\\0: Not triggered\\1: Triggered
  [7] LP_PDMA_AHB_TASK_OUT_START_CH0_ST — Represents LP_PDMA_AHB_task_out_start_ch0 trigger status.\\0: Not triggered\\1: Triggered
  [6] LP_PDMA_AHB_TASK_IN_START_CH1_ST — Represents LP_PDMA_AHB_task_in_start_ch1 trigger status.\\0: Not triggered\\1: Triggered
  [5] LP_PDMA_AHB_TASK_IN_START_CH0_ST — Represents LP_PDMA_AHB_task_in_start_ch0 trigger status.\\0: Not triggered\\1: Triggered
  [n] PDMA_AHB_TASK_OUT_START_CH{n}_ST (n=0..4) — Represents PDMA_AHB_task_out_start_ch{n} trigger status.\\0: Not triggered\\1: Triggered
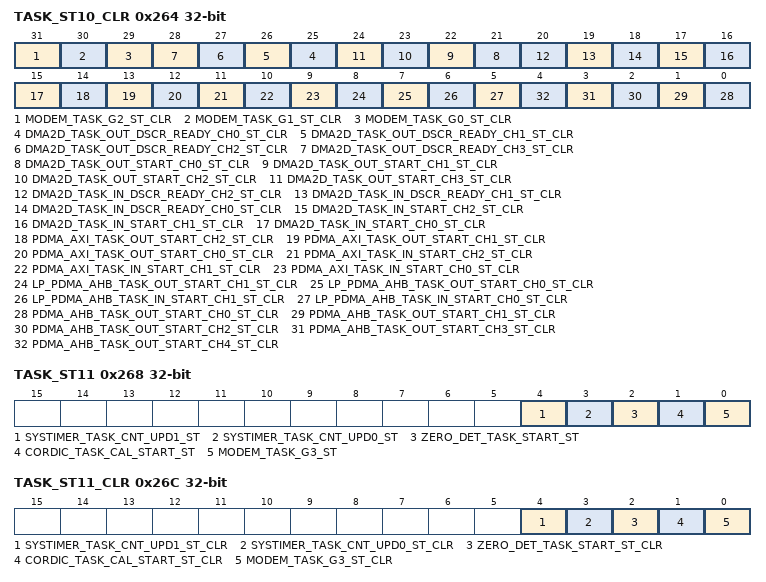
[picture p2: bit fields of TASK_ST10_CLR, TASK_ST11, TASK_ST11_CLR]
0x264 TASK_ST10_CLR wo — Tasks trigger status clear register
  [31] MODEM_TASK_G2_ST_CLR — Configures whether or not to clear MODEM_task_g2 trigger status.\\0: Invalid, No effect\\1: Clear
  [30] MODEM_TASK_G1_ST_CLR — Configures whether or not to clear MODEM_task_g1 trigger status.\\0: Invalid, No effect\\1: Clear
  [29] MODEM_TASK_G0_ST_CLR — Configures whether or not to clear MODEM_task_g0 trigger status.\\0: Invalid, No effect\\1: Clear
  [n+25] DMA2D_TASK_OUT_DSCR_READY_CH{n}_ST_CLR (n=0..3) — Configures whether or not to clear DMA2D_task_out_dscr_ready_ch{n} trigger status.\\0: Invalid, No effect\\1: Clear
  [n+21] DMA2D_TASK_OUT_START_CH{n}_ST_CLR (n=0..3) — Configures whether or not to clear DMA2D_task_out_start_ch{n} trigger status.\\0: Invalid, No effect\\1: Clear
  [20] DMA2D_TASK_IN_DSCR_READY_CH2_ST_CLR — Configures whether or not to clear DMA2D_task_in_dscr_ready_ch2 trigger status.\\0: Invalid, No effect\\1: Clear
  [19] DMA2D_TASK_IN_DSCR_READY_CH1_ST_CLR — Configures whether or not to clear DMA2D_task_in_dscr_ready_ch1 trigger status.\\0: Invalid, No effect\\1: Clear
  [18] DMA2D_TASK_IN_DSCR_READY_CH0_ST_CLR — Configures whether or not to clear DMA2D_task_in_dscr_ready_ch0 trigger status.\\0: Invalid, No effect\\1: Clear
  [17] DMA2D_TASK_IN_START_CH2_ST_CLR — Configures whether or not to clear DMA2D_task_in_start_ch2 trigger status.\\0: Invalid, No effect\\1: Clear
  [16] DMA2D_TASK_IN_START_CH1_ST_CLR — Configures whether or not to clear DMA2D_task_in_start_ch1 trigger status.\\0: Invalid, No effect\\1: Clear
  [15] DMA2D_TASK_IN_START_CH0_ST_CLR — Configures whether or not to clear DMA2D_task_in_start_ch0 trigger status.\\0: Invalid, No effect\\1: Clear
  [14] PDMA_AXI_TASK_OUT_START_CH2_ST_CLR — Configures whether or not to clear PDMA_AXI_task_out_start_ch2 trigger status.\\0: Invalid, No effect\\1: Clear
  [13] PDMA_AXI_TASK_OUT_START_CH1_ST_CLR — Configures whether or not to clear PDMA_AXI_task_out_start_ch1 trigger status.\\0: Invalid, No effect\\1: Clear
  [12] PDMA_AXI_TASK_OUT_START_CH0_ST_CLR — Configures whether or not to clear PDMA_AXI_task_out_start_ch0 trigger status.\\0: Invalid, No effect\\1: Clear
  [11] PDMA_AXI_TASK_IN_START_CH2_ST_CLR — Configures whether or not to clear PDMA_AXI_task_in_start_ch2 trigger status.\\0: Invalid, No effect\\1: Clear
  [10] PDMA_AXI_TASK_IN_START_CH1_ST_CLR — Configures whether or not to clear PDMA_AXI_task_in_start_ch1 trigger status.\\0: Invalid, No effect\\1: Clear
  [9] PDMA_AXI_TASK_IN_START_CH0_ST_CLR — Configures whether or not to clear PDMA_AXI_task_in_start_ch0 trigger status.\\0: Invalid, No effect\\1: Clear
  [8] LP_PDMA_AHB_TASK_OUT_START_CH1_ST_CLR — Configures whether or not to clear LP_PDMA_AHB_task_out_start_ch1 trigger status.\\0: Invalid, No effect\\1: Clear
  [7] LP_PDMA_AHB_TASK_OUT_START_CH0_ST_CLR — Configures whether or not to clear LP_PDMA_AHB_task_out_start_ch0 trigger status.\\0: Invalid, No effect\\1: Clear
  [6] LP_PDMA_AHB_TASK_IN_START_CH1_ST_CLR — Configures whether or not to clear LP_PDMA_AHB_task_in_start_ch1 trigger status.\\0: Invalid, No effect\\1: Clear
  [5] LP_PDMA_AHB_TASK_IN_START_CH0_ST_CLR — Configures whether or not to clear LP_PDMA_AHB_task_in_start_ch0 trigger status.\\0: Invalid, No effect\\1: Clear
  [n] PDMA_AHB_TASK_OUT_START_CH{n}_ST_CLR (n=0..4) — Configures whether or not to clear PDMA_AHB_task_out_start_ch{n} trigger status.\\0: Invalid, No effect\\1: Clear
0x268 TASK_ST11 — Tasks trigger status register
  [4] SYSTIMER_TASK_CNT_UPD1_ST — Represents SYSTIMER_task_cnt_upd1 trigger status.\\0: Not triggered\\1: Triggered
  [3] SYSTIMER_TASK_CNT_UPD0_ST — Represents SYSTIMER_task_cnt_upd0 trigger status.\\0: Not triggered\\1: Triggered
  [2] ZERO_DET_TASK_START_ST — Represents ZERO_DET_task_start trigger status.\\0: Not triggered\\1: Triggered
  [1] CORDIC_TASK_CAL_START_ST — Represents CORDIC_task_cal_start trigger status.\\0: Not triggered\\1: Triggered
  [0] MODEM_TASK_G3_ST — Represents MODEM_task_g3 trigger status.\\0: Not triggered\\1: Triggered
0x26C TASK_ST11_CLR wo — Tasks trigger status clear register
  [4] SYSTIMER_TASK_CNT_UPD1_ST_CLR — Configures whether or not to clear SYSTIMER_task_cnt_upd1 trigger status.\\0: Invalid, No effect\\1: Clear
  [3] SYSTIMER_TASK_CNT_UPD0_ST_CLR — Configures whether or not to clear SYSTIMER_task_cnt_upd0 trigger status.\\0: Invalid, No effect\\1: Clear
  [2] ZERO_DET_TASK_START_ST_CLR — Configures whether or not to clear ZERO_DET_task_start trigger status.\\0: Invalid, No effect\\1: Clear
  [1] CORDIC_TASK_CAL_START_ST_CLR — Configures whether or not to clear CORDIC_task_cal_start trigger status.\\0: Invalid, No effect\\1: Clear
  [0] MODEM_TASK_G3_ST_CLR — Configures whether or not to clear MODEM_task_g3 trigger status.\\0: Invalid, No effect\\1: Clear
0x270 CLK_EN — ETM clock enable register
  [0] CLK_EN — Configures whether or not to open register clock gate.\\0: Open the clock gate only when application writes registers\\1: Force open the clock gate for register
0x274 DATE reset 0x2501240 — ETM date register
  [27:0] DATE — Configures the version.
